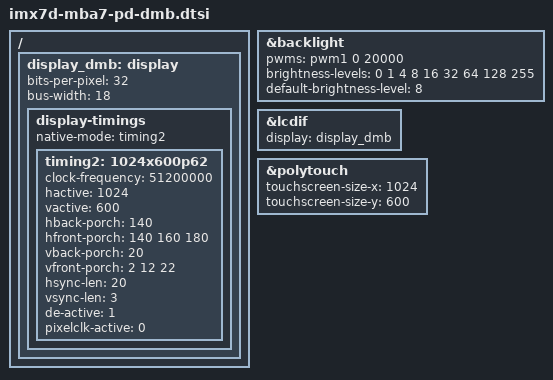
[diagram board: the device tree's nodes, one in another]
/*
 * Copyright (C) 2016 TQ Systems GmbH
 * Author: Marco Felsch <Marco.Felsch@tq-group.com>
 *
 * This file is dual-licensed: you can use it either under the terms
 * of the GPL or the X11 license, at your option. Note that this dual
 * licensing only applies to this file, and not this project as a
 * whole.
 *
 *  a) This file is free software; you can redistribute it and/or
 *     modify it under the terms of the GNU General Public License as
 *     published by the Free Software Foundation; either version 2 of the
 *     License, or (at your option) any later version.
 *
 *     This file is distributed in the hope that it will be useful,
 *     but WITHOUT ANY WARRANTY; without even the implied warranty of
 *     MERCHANTABILITY or FITNESS FOR A PARTICULAR PURPOSE.  See the
 *     GNU General Public License for more details.
 *
 * Or, alternatively,
 *
 *  b) Permission is hereby granted, free of charge, to any person
 *     obtaining a copy of this software and associated documentation
 *     files (the "Software"), to deal in the Software without
 *     restriction, including without limitation the rights to use,
 *     copy, modify, merge, publish, distribute, sublicense, and/or
 *     sell copies of the Software, and to permit persons to whom the
 *     Software is furnished to do so, subject to the following
 *     conditions:
 *
 *     The above copyright notice and this permission notice shall be
 *     included in all copies or substantial portions of the Software.
 *
 *     THE SOFTWARE IS PROVIDED "AS IS", WITHOUT WARRANTY OF ANY KIND,
 *     EXPRESS OR IMPLIED, INCLUDING BUT NOT LIMITED TO THE WARRANTIES
 *     OF MERCHANTABILITY, FITNESS FOR A PARTICULAR PURPOSE AND
 *     NONINFRINGEMENT. IN NO EVENT SHALL THE AUTHORS OR COPYRIGHT
 *     HOLDERS BE LIABLE FOR ANY CLAIM, DAMAGES OR OTHER LIABILITY,
 *     WHETHER IN AN ACTION OF CONTRACT, TORT OR OTHERWISE, ARISING
 *     FROM, OUT OF OR IN CONNECTION WITH THE SOFTWARE OR THE USE OR
 *     OTHER DEALINGS IN THE SOFTWARE.
 */

/ {
	display_dmb: display {
		bits-per-pixel = <32>; /* 32: RGB888/666 mode */
		bus-width = <18>;

		display-timings {
			native-mode = <&timing2>;

			/* S070WS12H-O-CT21 */
			timing2: 1024x600p62 {
				clock-frequency = <51200000>;
				hactive = <1024>;
				vactive = <600>;
				hback-porch = <140>;
				hfront-porch = <140 160 180>;
				vback-porch = <20>;
				vfront-porch = <2 12 22>;
				hsync-len = <20>;
				vsync-len = <3>;
				de-active = <1>;
				pixelclk-active = <0>;
			};
		};
	};
};

&backlight {
	pwms = <&pwm1 0 20000>; /* 50 kHz */
	brightness-levels = <0 1 4 8 16 32 64 128 255>;
	default-brightness-level = <8>;
	status = "okay";
};

&lcdif {
	display = <&display_dmb>;
};

&polytouch {
	touchscreen-size-x = <1024>;
	touchscreen-size-y = <600>;
	status = "okay";
};
